VERSION ""

NS_ :

BS_:

BU_: BMoS ECU_CAN4

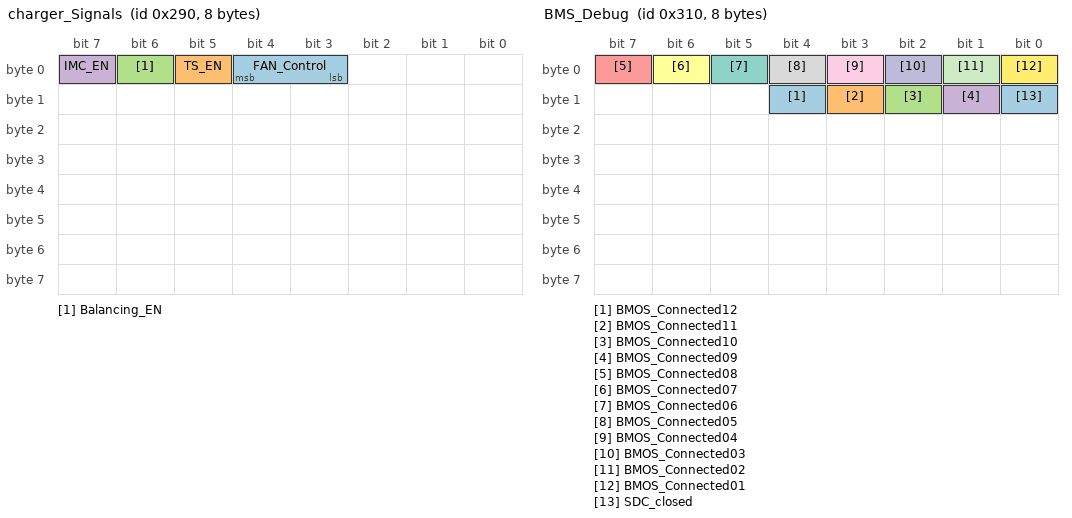
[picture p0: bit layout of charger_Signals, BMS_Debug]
BO_ 656 charger_Signals: 8 Vector__XXX
 SG_ FAN_Control : 3|2@1+ (1,0) [0|0] "" Vector__XXX
 SG_ TS_EN : 5|1@1+ (1,0) [0|1] "" Vector__XXX
 SG_ Balancing_EN : 6|1@1+ (1,0) [0|0] "" Vector__XXX
 SG_ IMC_EN : 7|1@1+ (1,0) [0|0] "" Vector__XXX

BO_ 1365 IMD: 8 Vector__XXX
 SG_ AMS_latched : 33|1@1+ (1,0) [0|1] "" Vector__XXX
 SG_ IMD_Latched : 32|1@1+ (1,0) [0|0] "" Vector__XXX

BO_ 624 charge_EN: 8 Vector__XXX
 SG_ Charge_EN : 0|1@1+ (1,0) [0|0] "" Vector__XXX
 SG_ Balance_FIN : 7|1@1+ (1,0) [0|0] "" Vector__XXX

BO_ 784 BMS_Debug: 8 Vector__XXX
 SG_ BMOS_Connected12 : 12|1@1+ (1,0) [0|0] "" Vector__XXX
 SG_ BMOS_Connected11 : 11|1@1+ (1,0) [0|0] "" Vector__XXX
 SG_ BMOS_Connected10 : 10|1@1+ (1,0) [0|0] "" Vector__XXX
 SG_ BMOS_Connected09 : 9|1@1+ (1,0) [0|0] "" Vector__XXX
 SG_ BMOS_Connected08 : 7|1@1+ (1,0) [0|0] "" Vector__XXX
 SG_ BMOS_Connected07 : 6|1@1+ (1,0) [0|0] "" Vector__XXX
 SG_ BMOS_Connected06 : 5|1@1+ (1,0) [0|0] "" Vector__XXX
 SG_ BMOS_Connected05 : 4|1@1+ (1,0) [0|0] "" Vector__XXX
 SG_ BMOS_Connected04 : 3|1@1+ (1,0) [0|0] "" Vector__XXX
 SG_ BMOS_Connected03 : 2|1@1+ (1,0) [0|0] "" Vector__XXX
 SG_ BMOS_Connected02 : 1|1@1+ (1,0) [0|0] "" Vector__XXX
 SG_ BMOS_Connected01 : 0|1@1+ (1,0) [0|0] "" Vector__XXX
 SG_ SDC_closed : 8|1@1+ (1,0) [0|0] "" Vector__XXX

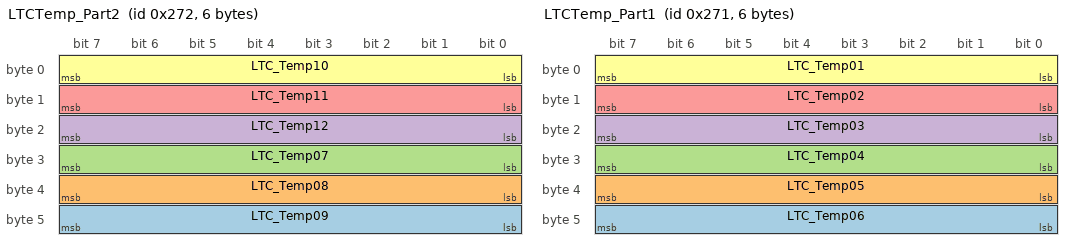
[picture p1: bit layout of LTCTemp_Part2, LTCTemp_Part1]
BO_ 626 LTCTemp_Part2: 6 BMoS
 SG_ LTC_Temp09 : 40|8@1- (1,0) [0|0] ""  ECU_CAN4
 SG_ LTC_Temp08 : 32|8@1- (1,0) [0|0] ""  ECU_CAN4
 SG_ LTC_Temp07 : 24|8@1- (1,0) [0|0] ""  ECU_CAN4
 SG_ LTC_Temp12 : 16|8@1- (1,0) [0|0] ""  ECU_CAN4
 SG_ LTC_Temp11 : 8|8@1- (1,0) [0|0] ""  ECU_CAN4
 SG_ LTC_Temp10 : 0|8@1- (1,0) [0|0] ""  ECU_CAN4

BO_ 625 LTCTemp_Part1: 6 BMoS
 SG_ LTC_Temp06 : 40|8@1- (1,0) [0|0] ""  ECU_CAN4
 SG_ LTC_Temp05 : 32|8@1- (1,0) [0|0] ""  ECU_CAN4
 SG_ LTC_Temp04 : 24|8@1- (1,0) [0|0] ""  ECU_CAN4
 SG_ LTC_Temp03 : 16|8@1- (1,0) [0|0] ""  ECU_CAN4
 SG_ LTC_Temp02 : 8|8@1- (1,0) [0|0] ""  ECU_CAN4
 SG_ LTC_Temp01 : 0|8@1- (1,0) [0|0] ""  ECU_CAN4

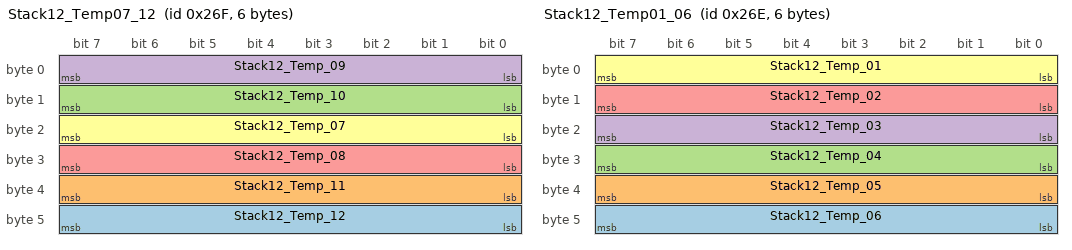
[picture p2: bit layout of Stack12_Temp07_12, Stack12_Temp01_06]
BO_ 623 Stack12_Temp07_12: 6 BMoS
 SG_ Stack12_Temp_12 : 40|8@1+ (1,0) [0|0] "°C" Vector__XXX
 SG_ Stack12_Temp_11 : 32|8@1+ (1,0) [0|0] "°C" Vector__XXX
 SG_ Stack12_Temp_10 : 8|8@1+ (1,0) [0|0] "°C" Vector__XXX
 SG_ Stack12_Temp_09 : 0|8@1+ (1,0) [0|0] "°C" Vector__XXX
 SG_ Stack12_Temp_08 : 24|8@1+ (1,0) [0|0] "°C"  ECU_CAN4
 SG_ Stack12_Temp_07 : 16|8@1+ (1,0) [0|0] "°C"  ECU_CAN4

BO_ 622 Stack12_Temp01_06: 6 BMoS
 SG_ Stack12_Temp_06 : 40|8@1+ (1,0) [0|0] "°C" Vector__XXX
 SG_ Stack12_Temp_05 : 32|8@1+ (1,0) [0|0] "°C" Vector__XXX
 SG_ Stack12_Temp_04 : 24|8@1+ (1,0) [0|0] "°C"  ECU_CAN4
 SG_ Stack12_Temp_03 : 16|8@1+ (1,0) [0|0] "°C"  ECU_CAN4
 SG_ Stack12_Temp_02 : 8|8@1+ (1,0) [0|0] "°C"  ECU_CAN4
 SG_ Stack12_Temp_01 : 0|8@1+ (1,0) [0|0] "°C"  ECU_CAN4

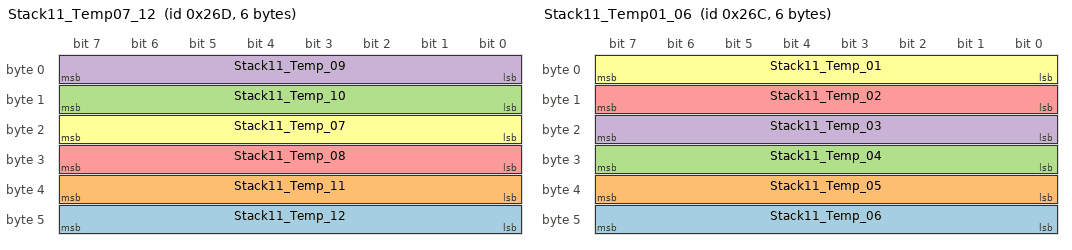
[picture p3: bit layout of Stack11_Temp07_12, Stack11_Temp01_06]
BO_ 621 Stack11_Temp07_12: 6 BMoS
 SG_ Stack11_Temp_12 : 40|8@1+ (1,0) [0|0] "°C" Vector__XXX
 SG_ Stack11_Temp_11 : 32|8@1+ (1,0) [0|0] "°C" Vector__XXX
 SG_ Stack11_Temp_10 : 8|8@1+ (1,0) [0|0] "°C" Vector__XXX
 SG_ Stack11_Temp_09 : 0|8@1+ (1,0) [0|0] "°C" Vector__XXX
 SG_ Stack11_Temp_08 : 24|8@1+ (1,0) [0|0] "°C"  ECU_CAN4
 SG_ Stack11_Temp_07 : 16|8@1+ (1,0) [0|0] "°C"  ECU_CAN4

BO_ 620 Stack11_Temp01_06: 6 BMoS
 SG_ Stack11_Temp_06 : 40|8@1+ (1,0) [0|0] "°C" Vector__XXX
 SG_ Stack11_Temp_05 : 32|8@1+ (1,0) [0|0] "°C" Vector__XXX
 SG_ Stack11_Temp_04 : 24|8@1+ (1,0) [0|0] "°C"  ECU_CAN4
 SG_ Stack11_Temp_03 : 16|8@1+ (1,0) [0|0] "°C"  ECU_CAN4
 SG_ Stack11_Temp_02 : 8|8@1+ (1,0) [0|0] "°C"  ECU_CAN4
 SG_ Stack11_Temp_01 : 0|8@1+ (1,0) [0|0] "°C"  ECU_CAN4

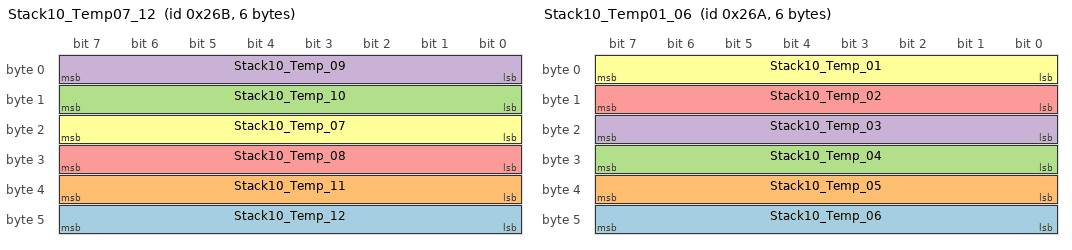
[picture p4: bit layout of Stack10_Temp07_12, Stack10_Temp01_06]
BO_ 619 Stack10_Temp07_12: 6 BMoS
 SG_ Stack10_Temp_12 : 40|8@1+ (1,0) [0|0] "°C" Vector__XXX
 SG_ Stack10_Temp_11 : 32|8@1+ (1,0) [0|0] "°C" Vector__XXX
 SG_ Stack10_Temp_10 : 8|8@1+ (1,0) [0|0] "°C" Vector__XXX
 SG_ Stack10_Temp_09 : 0|8@1+ (1,0) [0|0] "°C" Vector__XXX
 SG_ Stack10_Temp_08 : 24|8@1+ (1,0) [0|0] "°C"  ECU_CAN4
 SG_ Stack10_Temp_07 : 16|8@1+ (1,0) [0|0] "°C"  ECU_CAN4

BO_ 618 Stack10_Temp01_06: 6 BMoS
 SG_ Stack10_Temp_06 : 40|8@1+ (1,0) [0|0] "°C" Vector__XXX
 SG_ Stack10_Temp_05 : 32|8@1+ (1,0) [0|0] "°C" Vector__XXX
 SG_ Stack10_Temp_04 : 24|8@1+ (1,0) [0|0] "°C"  ECU_CAN4
 SG_ Stack10_Temp_03 : 16|8@1+ (1,0) [0|0] "°C"  ECU_CAN4
 SG_ Stack10_Temp_02 : 8|8@1+ (1,0) [0|0] "°C"  ECU_CAN4
 SG_ Stack10_Temp_01 : 0|8@1+ (1,0) [0|0] "°C"  ECU_CAN4

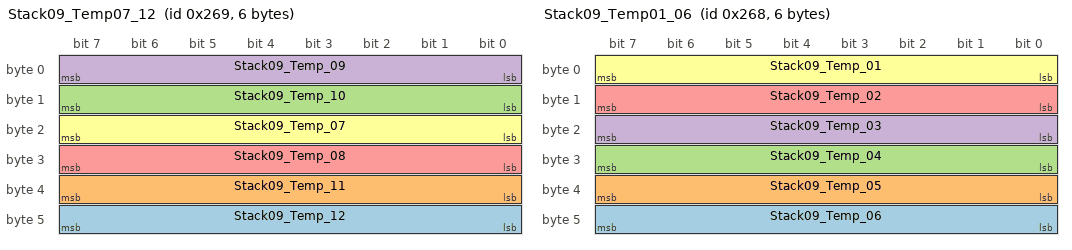
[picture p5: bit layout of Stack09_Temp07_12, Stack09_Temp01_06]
BO_ 617 Stack09_Temp07_12: 6 BMoS
 SG_ Stack09_Temp_12 : 40|8@1+ (1,0) [0|0] "°C" Vector__XXX
 SG_ Stack09_Temp_11 : 32|8@1+ (1,0) [0|0] "°C" Vector__XXX
 SG_ Stack09_Temp_10 : 8|8@1+ (1,0) [0|0] "°C" Vector__XXX
 SG_ Stack09_Temp_09 : 0|8@1+ (1,0) [0|0] "°C" Vector__XXX
 SG_ Stack09_Temp_08 : 24|8@1+ (1,0) [0|0] "°C"  ECU_CAN4
 SG_ Stack09_Temp_07 : 16|8@1+ (1,0) [0|0] "°C"  ECU_CAN4

BO_ 616 Stack09_Temp01_06: 6 BMoS
 SG_ Stack09_Temp_06 : 40|8@1+ (1,0) [0|0] "°C" Vector__XXX
 SG_ Stack09_Temp_05 : 32|8@1+ (1,0) [0|0] "°C" Vector__XXX
 SG_ Stack09_Temp_04 : 24|8@1+ (1,0) [0|0] "°C"  ECU_CAN4
 SG_ Stack09_Temp_03 : 16|8@1+ (1,0) [0|0] "°C"  ECU_CAN4
 SG_ Stack09_Temp_02 : 8|8@1+ (1,0) [0|0] "°C"  ECU_CAN4
 SG_ Stack09_Temp_01 : 0|8@1+ (1,0) [0|0] "°C"  ECU_CAN4

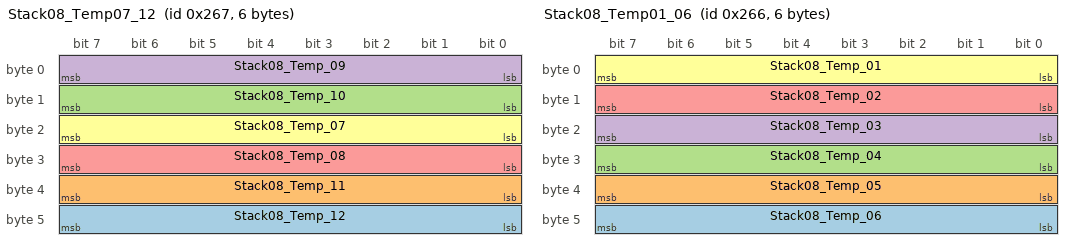
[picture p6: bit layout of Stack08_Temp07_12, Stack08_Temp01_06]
BO_ 615 Stack08_Temp07_12: 6 BMoS
 SG_ Stack08_Temp_12 : 40|8@1+ (1,0) [0|0] "°C" Vector__XXX
 SG_ Stack08_Temp_11 : 32|8@1+ (1,0) [0|0] "°C" Vector__XXX
 SG_ Stack08_Temp_10 : 8|8@1+ (1,0) [0|0] "°C" Vector__XXX
 SG_ Stack08_Temp_09 : 0|8@1+ (1,0) [0|0] "°C" Vector__XXX
 SG_ Stack08_Temp_08 : 24|8@1+ (1,0) [0|0] "°C"  ECU_CAN4
 SG_ Stack08_Temp_07 : 16|8@1+ (1,0) [0|0] "°C"  ECU_CAN4

BO_ 614 Stack08_Temp01_06: 6 BMoS
 SG_ Stack08_Temp_06 : 40|8@1+ (1,0) [0|0] "°C" Vector__XXX
 SG_ Stack08_Temp_05 : 32|8@1+ (1,0) [0|0] "°C" Vector__XXX
 SG_ Stack08_Temp_04 : 24|8@1+ (1,0) [0|0] "°C"  ECU_CAN4
 SG_ Stack08_Temp_03 : 16|8@1+ (1,0) [0|0] "°C"  ECU_CAN4
 SG_ Stack08_Temp_02 : 8|8@1+ (1,0) [0|0] "°C"  ECU_CAN4
 SG_ Stack08_Temp_01 : 0|8@1+ (1,0) [0|0] "°C"  ECU_CAN4

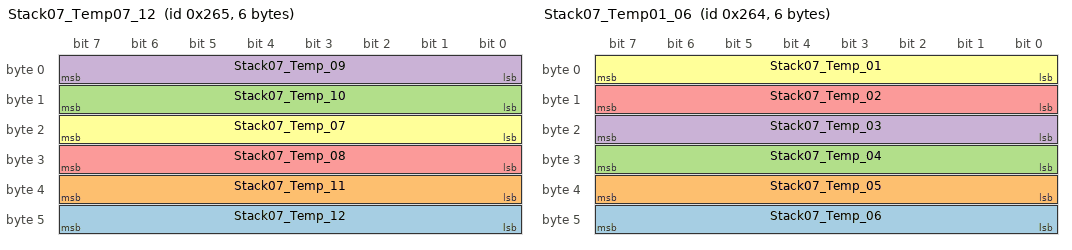
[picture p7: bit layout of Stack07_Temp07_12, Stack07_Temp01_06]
BO_ 613 Stack07_Temp07_12: 6 BMoS
 SG_ Stack07_Temp_12 : 40|8@1+ (1,0) [0|0] "°C" Vector__XXX
 SG_ Stack07_Temp_11 : 32|8@1+ (1,0) [0|0] "°C" Vector__XXX
 SG_ Stack07_Temp_10 : 8|8@1+ (1,0) [0|0] "°C" Vector__XXX
 SG_ Stack07_Temp_09 : 0|8@1+ (1,0) [0|0] "°C" Vector__XXX
 SG_ Stack07_Temp_08 : 24|8@1+ (1,0) [0|0] "°C"  ECU_CAN4
 SG_ Stack07_Temp_07 : 16|8@1+ (1,0) [0|0] "°C"  ECU_CAN4

BO_ 612 Stack07_Temp01_06: 6 BMoS
 SG_ Stack07_Temp_06 : 40|8@1+ (1,0) [0|0] "°C" Vector__XXX
 SG_ Stack07_Temp_05 : 32|8@1+ (1,0) [0|0] "°C" Vector__XXX
 SG_ Stack07_Temp_04 : 24|8@1+ (1,0) [0|0] "°C"  ECU_CAN4
 SG_ Stack07_Temp_03 : 16|8@1+ (1,0) [0|0] "°C"  ECU_CAN4
 SG_ Stack07_Temp_02 : 8|8@1+ (1,0) [0|0] "°C"  ECU_CAN4
 SG_ Stack07_Temp_01 : 0|8@1+ (1,0) [0|0] "°C"  ECU_CAN4

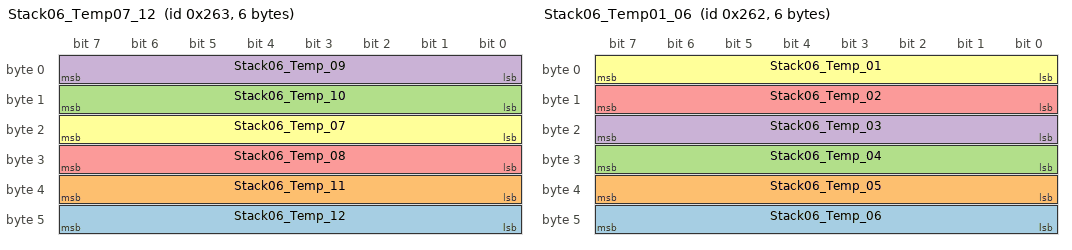
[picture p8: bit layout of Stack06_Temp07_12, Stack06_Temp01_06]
BO_ 611 Stack06_Temp07_12: 6 BMoS
 SG_ Stack06_Temp_12 : 40|8@1+ (1,0) [0|0] "°C" Vector__XXX
 SG_ Stack06_Temp_11 : 32|8@1+ (1,0) [0|0] "°C" Vector__XXX
 SG_ Stack06_Temp_10 : 8|8@1+ (1,0) [0|0] "°C" Vector__XXX
 SG_ Stack06_Temp_09 : 0|8@1+ (1,0) [0|0] "°C" Vector__XXX
 SG_ Stack06_Temp_08 : 24|8@1+ (1,0) [0|0] "°C"  ECU_CAN4
 SG_ Stack06_Temp_07 : 16|8@1+ (1,0) [0|0] "°C"  ECU_CAN4

BO_ 610 Stack06_Temp01_06: 6 BMoS
 SG_ Stack06_Temp_06 : 40|8@1+ (1,0) [0|0] "°C" Vector__XXX
 SG_ Stack06_Temp_05 : 32|8@1+ (1,0) [0|0] "°C" Vector__XXX
 SG_ Stack06_Temp_04 : 24|8@1+ (1,0) [0|0] "°C"  ECU_CAN4
 SG_ Stack06_Temp_03 : 16|8@1+ (1,0) [0|0] "°C"  ECU_CAN4
 SG_ Stack06_Temp_02 : 8|8@1+ (1,0) [0|0] "°C"  ECU_CAN4
 SG_ Stack06_Temp_01 : 0|8@1+ (1,0) [0|0] "°C"  ECU_CAN4

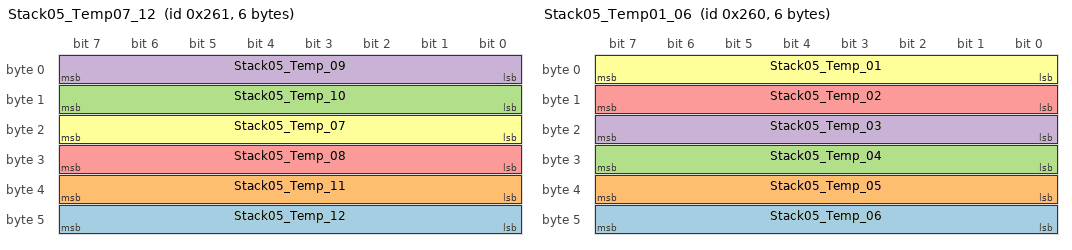
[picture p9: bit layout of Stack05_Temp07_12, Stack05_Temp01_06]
BO_ 609 Stack05_Temp07_12: 6 BMoS
 SG_ Stack05_Temp_12 : 40|8@1+ (1,0) [0|0] "°C" Vector__XXX
 SG_ Stack05_Temp_11 : 32|8@1+ (1,0) [0|0] "°C" Vector__XXX
 SG_ Stack05_Temp_10 : 8|8@1+ (1,0) [0|0] "°C" Vector__XXX
 SG_ Stack05_Temp_09 : 0|8@1+ (1,0) [0|0] "°C" Vector__XXX
 SG_ Stack05_Temp_08 : 24|8@1+ (1,0) [0|0] "°C"  ECU_CAN4
 SG_ Stack05_Temp_07 : 16|8@1+ (1,0) [0|0] "°C"  ECU_CAN4

BO_ 608 Stack05_Temp01_06: 6 BMoS
 SG_ Stack05_Temp_06 : 40|8@1+ (1,0) [0|0] "°C" Vector__XXX
 SG_ Stack05_Temp_05 : 32|8@1+ (1,0) [0|0] "°C" Vector__XXX
 SG_ Stack05_Temp_04 : 24|8@1+ (1,0) [0|0] "°C"  ECU_CAN4
 SG_ Stack05_Temp_03 : 16|8@1+ (1,0) [0|0] "°C"  ECU_CAN4
 SG_ Stack05_Temp_02 : 8|8@1+ (1,0) [0|0] "°C"  ECU_CAN4
 SG_ Stack05_Temp_01 : 0|8@1+ (1,0) [0|0] "°C"  ECU_CAN4

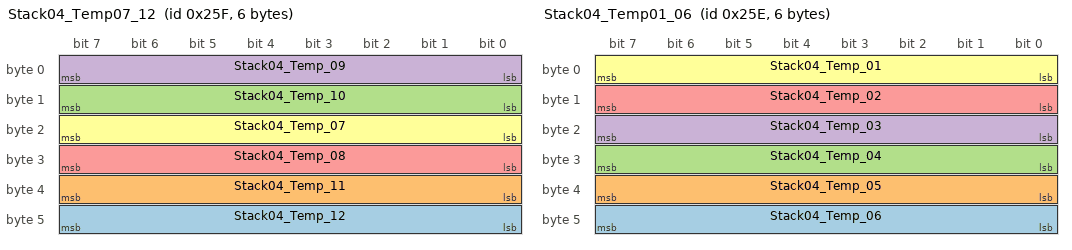
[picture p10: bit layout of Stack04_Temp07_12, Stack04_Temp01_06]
BO_ 607 Stack04_Temp07_12: 6 BMoS
 SG_ Stack04_Temp_12 : 40|8@1+ (1,0) [0|0] "°C" Vector__XXX
 SG_ Stack04_Temp_11 : 32|8@1+ (1,0) [0|0] "°C" Vector__XXX
 SG_ Stack04_Temp_10 : 8|8@1+ (1,0) [0|0] "°C" Vector__XXX
 SG_ Stack04_Temp_09 : 0|8@1+ (1,0) [0|0] "°C" Vector__XXX
 SG_ Stack04_Temp_08 : 24|8@1+ (1,0) [0|0] "°C"  ECU_CAN4
 SG_ Stack04_Temp_07 : 16|8@1+ (1,0) [0|0] "°C"  ECU_CAN4

BO_ 606 Stack04_Temp01_06: 6 BMoS
 SG_ Stack04_Temp_06 : 40|8@1+ (1,0) [0|0] "°C" Vector__XXX
 SG_ Stack04_Temp_05 : 32|8@1+ (1,0) [0|0] "°C" Vector__XXX
 SG_ Stack04_Temp_04 : 24|8@1+ (1,0) [0|0] "°C"  ECU_CAN4
 SG_ Stack04_Temp_03 : 16|8@1+ (1,0) [0|0] "°C"  ECU_CAN4
 SG_ Stack04_Temp_02 : 8|8@1+ (1,0) [0|0] "°C"  ECU_CAN4
 SG_ Stack04_Temp_01 : 0|8@1+ (1,0) [0|0] "°C"  ECU_CAN4

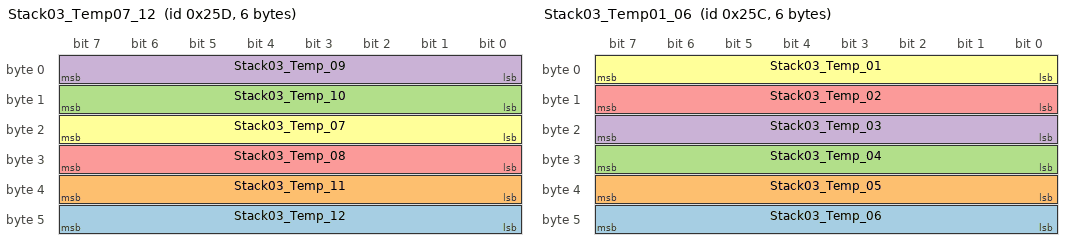
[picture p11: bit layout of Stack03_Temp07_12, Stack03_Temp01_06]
BO_ 605 Stack03_Temp07_12: 6 BMoS
 SG_ Stack03_Temp_12 : 40|8@1+ (1,0) [0|0] "°C" Vector__XXX
 SG_ Stack03_Temp_11 : 32|8@1+ (1,0) [0|0] "°C" Vector__XXX
 SG_ Stack03_Temp_10 : 8|8@1+ (1,0) [0|0] "°C" Vector__XXX
 SG_ Stack03_Temp_09 : 0|8@1+ (1,0) [0|0] "°C" Vector__XXX
 SG_ Stack03_Temp_08 : 24|8@1+ (1,0) [0|0] "°C"  ECU_CAN4
 SG_ Stack03_Temp_07 : 16|8@1+ (1,0) [0|0] "°C"  ECU_CAN4

BO_ 604 Stack03_Temp01_06: 6 BMoS
 SG_ Stack03_Temp_06 : 40|8@1+ (1,0) [0|0] "°C" Vector__XXX
 SG_ Stack03_Temp_05 : 32|8@1+ (1,0) [0|0] "°C" Vector__XXX
 SG_ Stack03_Temp_04 : 24|8@1+ (1,0) [0|0] "°C"  ECU_CAN4
 SG_ Stack03_Temp_03 : 16|8@1+ (1,0) [0|0] "°C"  ECU_CAN4
 SG_ Stack03_Temp_02 : 8|8@1+ (1,0) [0|0] "°C"  ECU_CAN4
 SG_ Stack03_Temp_01 : 0|8@1+ (1,0) [0|0] "°C"  ECU_CAN4

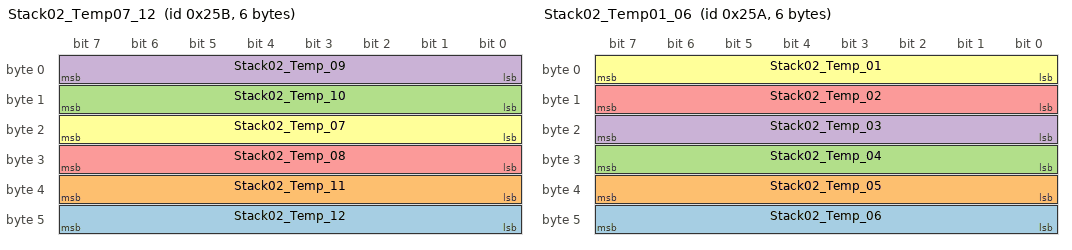
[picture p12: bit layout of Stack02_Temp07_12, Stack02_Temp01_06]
BO_ 603 Stack02_Temp07_12: 6 BMoS
 SG_ Stack02_Temp_12 : 40|8@1+ (1,0) [0|0] "°C" Vector__XXX
 SG_ Stack02_Temp_11 : 32|8@1+ (1,0) [0|0] "°C" Vector__XXX
 SG_ Stack02_Temp_10 : 8|8@1+ (1,0) [0|0] "°C" Vector__XXX
 SG_ Stack02_Temp_09 : 0|8@1+ (1,0) [0|0] "°C" Vector__XXX
 SG_ Stack02_Temp_08 : 24|8@1+ (1,0) [0|0] "°C"  ECU_CAN4
 SG_ Stack02_Temp_07 : 16|8@1+ (1,0) [0|0] "°C"  ECU_CAN4

BO_ 602 Stack02_Temp01_06: 6 BMoS
 SG_ Stack02_Temp_06 : 40|8@1+ (1,0) [0|0] "°C" Vector__XXX
 SG_ Stack02_Temp_05 : 32|8@1+ (1,0) [0|0] "°C" Vector__XXX
 SG_ Stack02_Temp_04 : 24|8@1+ (1,0) [0|0] "°C"  ECU_CAN4
 SG_ Stack02_Temp_03 : 16|8@1+ (1,0) [0|0] "°C"  ECU_CAN4
 SG_ Stack02_Temp_02 : 8|8@1+ (1,0) [0|0] "°C"  ECU_CAN4
 SG_ Stack02_Temp_01 : 0|8@1+ (1,0) [0|0] "°C"  ECU_CAN4

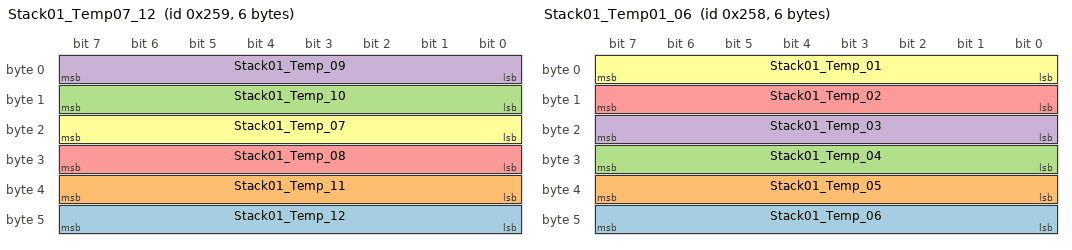
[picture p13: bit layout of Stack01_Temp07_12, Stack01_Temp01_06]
BO_ 601 Stack01_Temp07_12: 6 BMoS
 SG_ Stack01_Temp_12 : 40|8@1+ (1,0) [0|0] "°C" Vector__XXX
 SG_ Stack01_Temp_11 : 32|8@1+ (1,0) [0|0] "°C" Vector__XXX
 SG_ Stack01_Temp_10 : 8|8@1+ (1,0) [0|0] "°C" Vector__XXX
 SG_ Stack01_Temp_09 : 0|8@1+ (1,0) [0|0] "°C" Vector__XXX
 SG_ Stack01_Temp_08 : 24|8@1+ (1,0) [0|0] "°C"  ECU_CAN4
 SG_ Stack01_Temp_07 : 16|8@1+ (1,0) [0|0] "°C"  ECU_CAN4

BO_ 600 Stack01_Temp01_06: 6 BMoS
 SG_ Stack01_Temp_06 : 40|8@1+ (1,0) [0|0] "°C" Vector__XXX
 SG_ Stack01_Temp_05 : 32|8@1+ (1,0) [0|0] "°C" Vector__XXX
 SG_ Stack01_Temp_04 : 24|8@1+ (1,0) [0|0] "°C"  ECU_CAN4
 SG_ Stack01_Temp_03 : 16|8@1+ (1,0) [0|0] "°C"  ECU_CAN4
 SG_ Stack01_Temp_02 : 8|8@1+ (1,0) [0|0] "°C"  ECU_CAN4
 SG_ Stack01_Temp_01 : 0|8@1+ (1,0) [0|0] "°C"  ECU_CAN4

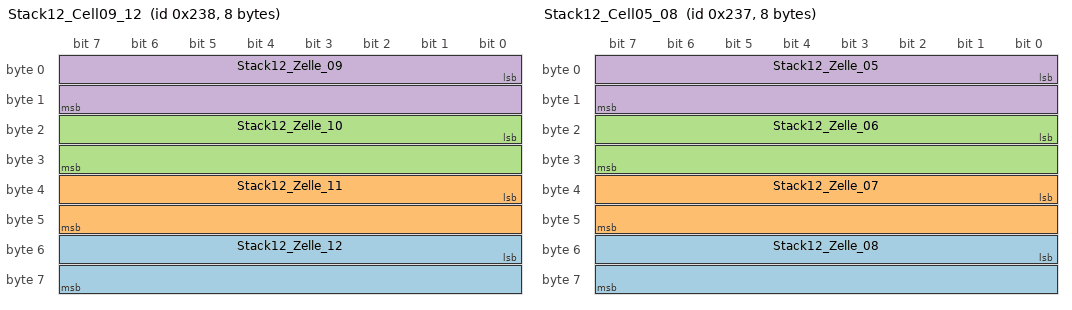
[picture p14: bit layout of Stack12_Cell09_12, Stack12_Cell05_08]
BO_ 568 Stack12_Cell09_12: 8 BMoS
 SG_ Stack12_Zelle_12 : 48|16@1+ (1,0) [0|0] "100 uV"  ECU_CAN4
 SG_ Stack12_Zelle_11 : 32|16@1+ (1,0) [0|0] "100 uV"  ECU_CAN4
 SG_ Stack12_Zelle_10 : 16|16@1+ (1,0) [0|0] "100 uV"  ECU_CAN4
 SG_ Stack12_Zelle_09 : 0|16@1+ (1,0) [0|0] "100 uV"  ECU_CAN4

BO_ 567 Stack12_Cell05_08: 8 BMoS
 SG_ Stack12_Zelle_08 : 48|16@1+ (1,0) [0|0] "100 uV"  ECU_CAN4
 SG_ Stack12_Zelle_07 : 32|16@1+ (1,0) [0|0] "100 uV"  ECU_CAN4
 SG_ Stack12_Zelle_06 : 16|16@1+ (1,0) [0|0] "100 uV"  ECU_CAN4
 SG_ Stack12_Zelle_05 : 0|16@1+ (1,0) [0|0] "100 uV"  ECU_CAN4

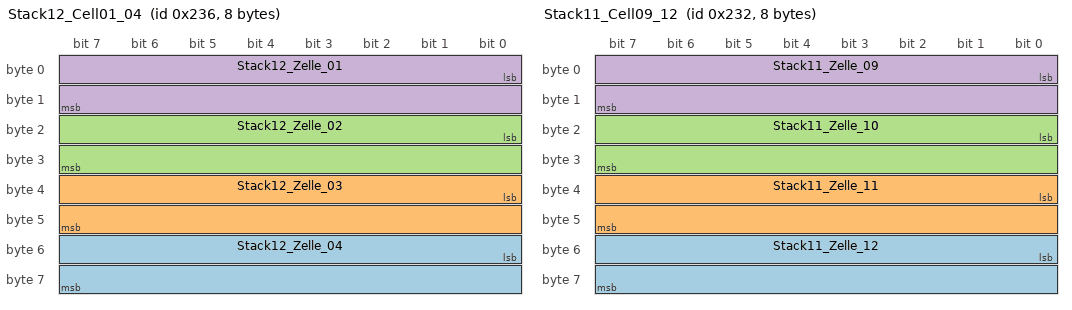
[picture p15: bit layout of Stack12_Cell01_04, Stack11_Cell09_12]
BO_ 566 Stack12_Cell01_04: 8 BMoS
 SG_ Stack12_Zelle_04 : 48|16@1+ (1,0) [0|0] "100 uV"  ECU_CAN4
 SG_ Stack12_Zelle_03 : 32|16@1+ (1,0) [0|0] "100 uV"  ECU_CAN4
 SG_ Stack12_Zelle_02 : 16|16@1+ (1,0) [0|0] "100 uV"  ECU_CAN4
 SG_ Stack12_Zelle_01 : 0|16@1+ (1,0) [0|0] "100 uV"  ECU_CAN4

BO_ 562 Stack11_Cell09_12: 8 BMoS
 SG_ Stack11_Zelle_12 : 48|16@1+ (1,0) [0|0] "100 uV"  ECU_CAN4
 SG_ Stack11_Zelle_11 : 32|16@1+ (1,0) [0|0] "100 uV"  ECU_CAN4
 SG_ Stack11_Zelle_10 : 16|16@1+ (1,0) [0|0] "100 uV"  ECU_CAN4
 SG_ Stack11_Zelle_09 : 0|16@1+ (1,0) [0|0] "100 uV"  ECU_CAN4

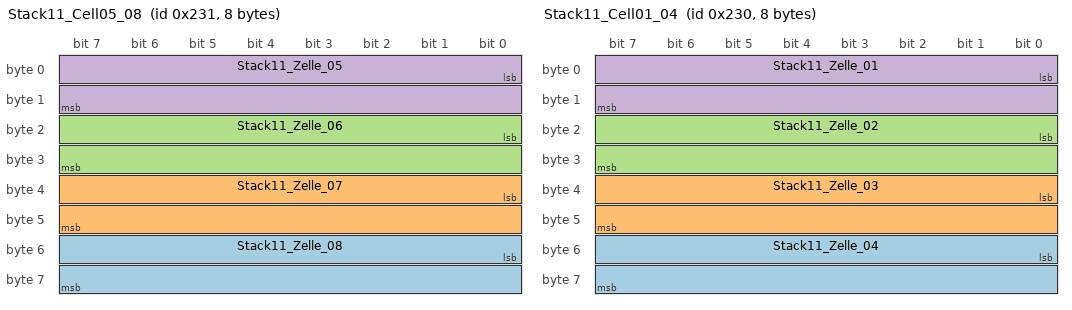
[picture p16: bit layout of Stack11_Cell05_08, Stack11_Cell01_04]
BO_ 561 Stack11_Cell05_08: 8 BMoS
 SG_ Stack11_Zelle_08 : 48|16@1+ (1,0) [0|0] "100 uV"  ECU_CAN4
 SG_ Stack11_Zelle_07 : 32|16@1+ (1,0) [0|0] "100 uV"  ECU_CAN4
 SG_ Stack11_Zelle_06 : 16|16@1+ (1,0) [0|0] "100 uV"  ECU_CAN4
 SG_ Stack11_Zelle_05 : 0|16@1+ (1,0) [0|0] "100 uV"  ECU_CAN4

BO_ 560 Stack11_Cell01_04: 8 BMoS
 SG_ Stack11_Zelle_04 : 48|16@1+ (1,0) [0|0] "100 uV"  ECU_CAN4
 SG_ Stack11_Zelle_03 : 32|16@1+ (1,0) [0|0] "100 uV"  ECU_CAN4
 SG_ Stack11_Zelle_02 : 16|16@1+ (1,0) [0|0] "100 uV"  ECU_CAN4
 SG_ Stack11_Zelle_01 : 0|16@1+ (1,0) [0|0] "100 uV"  ECU_CAN4

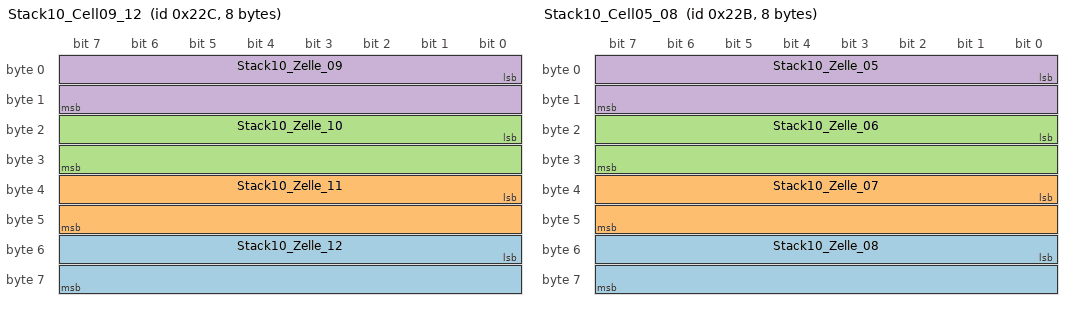
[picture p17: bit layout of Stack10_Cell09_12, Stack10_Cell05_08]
BO_ 556 Stack10_Cell09_12: 8 BMoS
 SG_ Stack10_Zelle_12 : 48|16@1+ (1,0) [0|0] "100 uV"  ECU_CAN4
 SG_ Stack10_Zelle_11 : 32|16@1+ (1,0) [0|0] "100 uV"  ECU_CAN4
 SG_ Stack10_Zelle_10 : 16|16@1+ (1,0) [0|0] "100 uV"  ECU_CAN4
 SG_ Stack10_Zelle_09 : 0|16@1+ (1,0) [0|0] "100 uV"  ECU_CAN4

BO_ 555 Stack10_Cell05_08: 8 BMoS
 SG_ Stack10_Zelle_08 : 48|16@1+ (1,0) [0|0] "100 uV"  ECU_CAN4
 SG_ Stack10_Zelle_07 : 32|16@1+ (1,0) [0|0] "100 uV"  ECU_CAN4
 SG_ Stack10_Zelle_06 : 16|16@1+ (1,0) [0|0] "100 uV"  ECU_CAN4
 SG_ Stack10_Zelle_05 : 0|16@1+ (1,0) [0|0] "100 uV"  ECU_CAN4

BO_ 554 Stack10_Cell01_04: 8 BMoS
 SG_ Stack10_Zelle_04 : 48|16@1+ (1,0) [0|0] "100 uV"  ECU_CAN4
 SG_ Stack10_Zelle_03 : 32|16@1+ (1,0) [0|0] "100 uV"  ECU_CAN4
 SG_ Stack10_Zelle_02 : 16|16@1+ (1,0) [0|0] "100 uV"  ECU_CAN4
 SG_ Stack10_Zelle_01 : 0|16@1+ (1,0) [0|0] "100 uV"  ECU_CAN4

BO_ 550 Stack09_Cell09_12: 8 BMoS
 SG_ Stack09_Zelle_12 : 48|16@1+ (1,0) [0|0] "100 uV"  ECU_CAN4
 SG_ Stack09_Zelle_11 : 32|16@1+ (1,0) [0|0] "100 uV"  ECU_CAN4
 SG_ Stack09_Zelle_10 : 16|16@1+ (1,0) [0|0] "100 uV"  ECU_CAN4
 SG_ Stack09_Zelle_09 : 0|16@1+ (1,0) [0|0] "100 uV"  ECU_CAN4

BO_ 549 Stack09_Cell05_08: 8 BMoS
 SG_ Stack09_Zelle_08 : 48|16@1+ (1,0) [0|0] "100 uV"  ECU_CAN4
 SG_ Stack09_Zelle_07 : 32|16@1+ (1,0) [0|0] "100 uV"  ECU_CAN4
 SG_ Stack09_Zelle_06 : 16|16@1+ (1,0) [0|0] "100 uV"  ECU_CAN4
 SG_ Stack09_Zelle_05 : 0|16@1+ (1,0) [0|0] "100 uV"  ECU_CAN4

BO_ 548 Stack09_Cell01_04: 8 BMoS
 SG_ Stack09_Zelle_04 : 48|16@1+ (1,0) [0|0] "100 uV"  ECU_CAN4
 SG_ Stack09_Zelle_03 : 32|16@1+ (1,0) [0|0] "100 uV"  ECU_CAN4
 SG_ Stack09_Zelle_02 : 16|16@1+ (1,0) [0|0] "100 uV"  ECU_CAN4
 SG_ Stack09_Zelle_01 : 0|16@1+ (1,0) [0|0] "100 uV"  ECU_CAN4

BO_ 544 Stack08_Cell09_12: 8 BMoS
 SG_ Stack08_Zelle_12 : 48|16@1+ (1,0) [0|0] "100 uV"  ECU_CAN4
 SG_ Stack08_Zelle_11 : 32|16@1+ (1,0) [0|0] "100 uV"  ECU_CAN4
 SG_ Stack08_Zelle_10 : 16|16@1+ (1,0) [0|0] "100 uV"  ECU_CAN4
 SG_ Stack08_Zelle_09 : 0|16@1+ (1,0) [0|0] "100 uV"  ECU_CAN4

BO_ 543 Stack08_Cell05_08: 8 BMoS
 SG_ Stack08_Zelle_08 : 48|16@1+ (1,0) [0|0] "100 uV"  ECU_CAN4
 SG_ Stack08_Zelle_07 : 32|16@1+ (1,0) [0|0] "100 uV"  ECU_CAN4
 SG_ Stack08_Zelle_06 : 16|16@1+ (1,0) [0|0] "100 uV"  ECU_CAN4
 SG_ Stack08_Zelle_05 : 0|16@1+ (1,0) [0|0] "100 uV"  ECU_CAN4

BO_ 542 Stack08_Cell01_04: 8 BMoS
 SG_ Stack08_Zelle_04 : 48|16@1+ (1,0) [0|0] "100 uV"  ECU_CAN4
 SG_ Stack08_Zelle_03 : 32|16@1+ (1,0) [0|0] "100 uV"  ECU_CAN4
 SG_ Stack08_Zelle_02 : 16|16@1+ (1,0) [0|0] "100 uV"  ECU_CAN4
 SG_ Stack08_Zelle_01 : 0|16@1+ (1,0) [0|0] "100 uV"  ECU_CAN4

BO_ 538 Stack07_Cell09_12: 8 BMoS
 SG_ Stack07_Zelle_12 : 48|16@1+ (1,0) [0|0] "100 uV"  ECU_CAN4
 SG_ Stack07_Zelle_11 : 32|16@1+ (1,0) [0|0] "100 uV"  ECU_CAN4
 SG_ Stack07_Zelle_10 : 16|16@1+ (1,0) [0|0] "100 uV"  ECU_CAN4
 SG_ Stack07_Zelle_09 : 0|16@1+ (1,0) [0|0] "100 uV"  ECU_CAN4

BO_ 537 Stack07_Cell05_08: 8 BMoS
 SG_ Stack07_Zelle_08 : 48|16@1+ (1,0) [0|0] "100 uV"  ECU_CAN4
 SG_ Stack07_Zelle_07 : 32|16@1+ (1,0) [0|0] "100 uV"  ECU_CAN4
 SG_ Stack07_Zelle_06 : 16|16@1+ (1,0) [0|0] "100 uV"  ECU_CAN4
 SG_ Stack07_Zelle_05 : 0|16@1+ (1,0) [0|0] "100 uV"  ECU_CAN4

BO_ 536 Stack07_Cell01_04: 8 BMoS
 SG_ Stack07_Zelle_04 : 48|16@1+ (1,0) [0|0] "100 uV"  ECU_CAN4
 SG_ Stack07_Zelle_03 : 32|16@1+ (1,0) [0|0] "100 uV"  ECU_CAN4
 SG_ Stack07_Zelle_02 : 16|16@1+ (1,0) [0|0] "100 uV"  ECU_CAN4
 SG_ Stack07_Zelle_01 : 0|16@1+ (1,0) [0|0] "100 uV"  ECU_CAN4

BO_ 532 Stack06_Cell09_12: 8 BMoS
 SG_ Stack06_Zelle_12 : 48|16@1+ (1,0) [0|0] "100 uV"  ECU_CAN4
 SG_ Stack06_Zelle_11 : 32|16@1+ (1,0) [0|0] "100 uV"  ECU_CAN4
 SG_ Stack06_Zelle_10 : 16|16@1+ (1,0) [0|0] "100 uV"  ECU_CAN4
 SG_ Stack06_Zelle_09 : 0|16@1+ (1,0) [0|0] "100 uV"  ECU_CAN4

BO_ 531 Stack06_Cell05_08: 8 BMoS
 SG_ Stack06_Zelle_08 : 48|16@1+ (1,0) [0|0] "100 uV"  ECU_CAN4
 SG_ Stack06_Zelle_07 : 32|16@1+ (1,0) [0|0] "100 uV"  ECU_CAN4
 SG_ Stack06_Zelle_06 : 16|16@1+ (1,0) [0|0] "100 uV"  ECU_CAN4
 SG_ Stack06_Zelle_05 : 0|16@1+ (1,0) [0|0] "100 uV"  ECU_CAN4

BO_ 530 Stack06_Cell01_04: 8 BMoS
 SG_ Stack06_Zelle_04 : 48|16@1+ (1,0) [0|0] "100 uV"  ECU_CAN4
 SG_ Stack06_Zelle_03 : 32|16@1+ (1,0) [0|0] "100 uV"  ECU_CAN4
 SG_ Stack06_Zelle_02 : 16|16@1+ (1,0) [0|0] "100 uV"  ECU_CAN4
 SG_ Stack06_Zelle_01 : 0|16@1+ (1,0) [0|0] "100 uV"  ECU_CAN4

BO_ 526 Stack05_Cell09_12: 8 BMoS
 SG_ Stack05_Zelle_12 : 48|16@1+ (1,0) [0|0] "100 uV"  ECU_CAN4
 SG_ Stack05_Zelle_11 : 32|16@1+ (1,0) [0|0] "100 uV"  ECU_CAN4
 SG_ Stack05_Zelle_10 : 16|16@1+ (1,0) [0|0] "100 uV"  ECU_CAN4
 SG_ Stack05_Zelle_09 : 0|16@1+ (1,0) [0|0] "100 uV"  ECU_CAN4

BO_ 525 Stack05_Cell05_08: 8 BMoS
 SG_ Stack05_Zelle_08 : 48|16@1+ (1,0) [0|0] "100 uV"  ECU_CAN4
 SG_ Stack05_Zelle_07 : 32|16@1+ (1,0) [0|0] "100 uV"  ECU_CAN4
 SG_ Stack05_Zelle_06 : 16|16@1+ (1,0) [0|0] "100 uV"  ECU_CAN4
 SG_ Stack05_Zelle_05 : 0|16@1+ (1,0) [0|0] "100 uV"  ECU_CAN4

BO_ 524 Stack05_Cell01_04: 8 BMoS
 SG_ Stack05_Zelle_04 : 48|16@1+ (1,0) [0|0] "100 uV"  ECU_CAN4
 SG_ Stack05_Zelle_03 : 32|16@1+ (1,0) [0|0] "100 uV"  ECU_CAN4
 SG_ Stack05_Zelle_02 : 16|16@1+ (1,0) [0|0] "100 uV"  ECU_CAN4
 SG_ Stack05_Zelle_01 : 0|16@1+ (1,0) [0|0] "100 uV"  ECU_CAN4

BO_ 520 Stack04_Cell09_12: 8 BMoS
 SG_ Stack04_Zelle_12 : 48|16@1+ (1,0) [0|0] "100 uV"  ECU_CAN4
 SG_ Stack04_Zelle_11 : 32|16@1+ (1,0) [0|0] "100 uV"  ECU_CAN4
 SG_ Stack04_Zelle_10 : 16|16@1+ (1,0) [0|0] "100 uV"  ECU_CAN4
 SG_ Stack04_Zelle_09 : 0|16@1+ (1,0) [0|0] "100 uV"  ECU_CAN4

BO_ 519 Stack04_Cell05_08: 8 BMoS
 SG_ Stack04_Zelle_08 : 48|16@1+ (1,0) [0|0] "100 uV"  ECU_CAN4
 SG_ Stack04_Zelle_07 : 32|16@1+ (1,0) [0|0] "100 uV"  ECU_CAN4
 SG_ Stack04_Zelle_06 : 16|16@1+ (1,0) [0|0] "100 uV"  ECU_CAN4
 SG_ Stack04_Zelle_05 : 0|16@1+ (1,0) [0|0] "100 uV"  ECU_CAN4

BO_ 518 Stack04_Cell01_04: 8 BMoS
 SG_ Stack04_Zelle_04 : 48|16@1+ (1,0) [0|0] "100 uV"  ECU_CAN4
 SG_ Stack04_Zelle_03 : 32|16@1+ (1,0) [0|0] "100 uV"  ECU_CAN4
 SG_ Stack04_Zelle_02 : 16|16@1+ (1,0) [0|0] "100 uV"  ECU_CAN4
 SG_ Stack04_Zelle_01 : 0|16@1+ (1,0) [0|0] "100 uV"  ECU_CAN4

BO_ 514 Stack03_Cell09_12: 8 BMoS
 SG_ Stack03_Zelle_12 : 48|16@1+ (1,0) [0|0] "100 uV"  ECU_CAN4
 SG_ Stack03_Zelle_11 : 32|16@1+ (1,0) [0|0] "100 uV"  ECU_CAN4
 SG_ Stack03_Zelle_10 : 16|16@1+ (1,0) [0|0] "100 uV"  ECU_CAN4
 SG_ Stack03_Zelle_09 : 0|16@1+ (1,0) [0|0] "100 uV"  ECU_CAN4

BO_ 513 Stack03_Cell05_08: 8 BMoS
 SG_ Stack03_Zelle_08 : 48|16@1+ (1,0) [0|0] "100 uV"  ECU_CAN4
 SG_ Stack03_Zelle_07 : 32|16@1+ (1,0) [0|0] "100 uV"  ECU_CAN4
 SG_ Stack03_Zelle_06 : 16|16@1+ (1,0) [0|0] "100 uV"  ECU_CAN4
 SG_ Stack03_Zelle_05 : 0|16@1+ (1,0) [0|0] "100 uV"  ECU_CAN4

BO_ 512 Stack03_Cell01_04: 8 BMoS
 SG_ Stack03_Zelle_04 : 48|16@1+ (1,0) [0|0] "100 uV"  ECU_CAN4
 SG_ Stack03_Zelle_03 : 32|16@1+ (1,0) [0|0] "100 uV"  ECU_CAN4
 SG_ Stack03_Zelle_02 : 16|16@1+ (1,0) [0|0] "100 uV"  ECU_CAN4
 SG_ Stack03_Zelle_01 : 0|16@1+ (1,0) [0|0] "100 uV"  ECU_CAN4

BO_ 508 Stack02_Cell09_12: 8 BMoS
 SG_ Stack02_Zelle_12 : 48|16@1+ (1,0) [0|0] "100 uV"  ECU_CAN4
 SG_ Stack02_Zelle_11 : 32|16@1+ (1,0) [0|0] "100 uV"  ECU_CAN4
 SG_ Stack02_Zelle_10 : 16|16@1+ (1,0) [0|0] "100 uV"  ECU_CAN4
 SG_ Stack02_Zelle_09 : 0|16@1+ (1,0) [0|0] "100 uV"  ECU_CAN4

BO_ 507 Stack02_Cell05_08: 8 BMoS
 SG_ Stack02_Zelle_08 : 48|16@1+ (1,0) [0|0] "100 uV"  ECU_CAN4
 SG_ Stack02_Zelle_07 : 32|16@1+ (1,0) [0|0] "100 uV"  ECU_CAN4
 SG_ Stack02_Zelle_06 : 16|16@1+ (1,0) [0|0] "100 uV"  ECU_CAN4
 SG_ Stack02_Zelle_05 : 0|16@1+ (1,0) [0|0] "100 uV"  ECU_CAN4

BO_ 506 Stack02_Cell01_04: 8 BMoS
 SG_ Stack02_Zelle_04 : 48|16@1+ (1,0) [0|0] "100 uV"  ECU_CAN4
 SG_ Stack02_Zelle_03 : 32|16@1+ (1,0) [0|0] "100 uV"  ECU_CAN4
 SG_ Stack02_Zelle_02 : 16|16@1+ (1,0) [0|0] "100 uV"  ECU_CAN4
 SG_ Stack02_Zelle_01 : 0|16@1+ (1,0) [0|0] "100 uV"  ECU_CAN4

BO_ 502 Stack01_Cell09_12: 8 BMoS
 SG_ Stack01_Zelle_12 : 48|16@1+ (1,0) [0|0] "100 uV"  ECU_CAN4
 SG_ Stack01_Zelle_11 : 32|16@1+ (1,0) [0|0] "100 uV"  ECU_CAN4
 SG_ Stack01_Zelle_10 : 16|16@1+ (1,0) [0|0] "100 uV"  ECU_CAN4
 SG_ Stack01_Zelle_09 : 0|16@1+ (1,0) [0|0] "100 uV"  ECU_CAN4

BO_ 501 Stack01_Cell05_08: 8 BMoS
 SG_ Stack01_Zelle_08 : 48|16@1+ (1,0) [0|0] "100 uV"  ECU_CAN4
 SG_ Stack01_Zelle_07 : 32|16@1+ (1,0) [0|0] "100 uV"  ECU_CAN4
 SG_ Stack01_Zelle_06 : 16|16@1+ (1,0) [0|0] "100 uV"  ECU_CAN4
 SG_ Stack01_Zelle_05 : 0|16@1+ (1,0) [0|0] "100 uV"  ECU_CAN4

BO_ 500 Stack01_Cell01_04: 8 BMoS
 SG_ Stack01_Zelle_04 : 48|16@1+ (1,0) [0|0] "100 uV"  ECU_CAN4
 SG_ Stack01_Zelle_03 : 32|16@1+ (1,0) [0|0] "100 uV"  ECU_CAN4
 SG_ Stack01_Zelle_02 : 16|16@1+ (1,0) [0|0] "100 uV"  ECU_CAN4
 SG_ Stack01_Zelle_01 : 0|16@1+ (1,0) [0|0] "100 uV"  ECU_CAN4

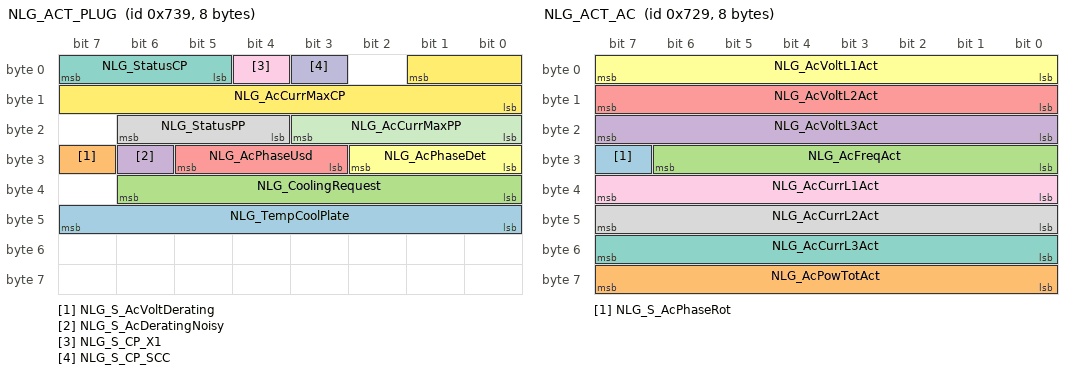
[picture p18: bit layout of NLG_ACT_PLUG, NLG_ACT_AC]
BO_ 1849 NLG_ACT_PLUG: 8 NLG6
 SG_ NLG_TempCoolPlate : 47|8@0+ (1,-50) [-50|204] "GradC"  Control
 SG_ NLG_S_AcVoltDerating : 31|1@0+ (1,0) [0|1] ""  Control
 SG_ NLG_CoolingRequest : 38|7@0+ (1,0) [0|100] "%"  Control
 SG_ NLG_S_AcDeratingNoisy : 30|1@0+ (1,0) [0|1] ""  Control
 SG_ NLG_AcPhaseUsd : 29|3@0+ (1,0) [0|7] ""  Control
 SG_ NLG_AcPhaseDet : 26|3@0+ (1,0) [0|7] ""  Control
 SG_ NLG_StatusCP : 7|3@0+ (1,0) [0|7] ""  Control
 SG_ NLG_StatusPP : 22|3@0+ (1,0) [0|7] ""  Control
 SG_ NLG_S_CP_X1 : 4|1@0+ (1,0) [0|1] ""  Control
 SG_ NLG_S_CP_SCC : 3|1@0+ (1,0) [0|1] ""  Control
 SG_ NLG_AcCurrMaxPP : 19|4@0+ (1,0) [0|15] ""  Control
 SG_ NLG_AcCurrMaxCP : 1|10@0+ (0.1,0) [0|80] "A"  Control

BO_ 1113 D_RS_NLG: 8 NLG6
 SG_ DiagDataResponse : 16|48@1+ (1,0) [0|0] ""  Control
 SG_ DiagTPCI : 8|8@1+ (1,0) [0|0] ""  Control
 SG_ DiagTA : 0|8@1+ (1,0) [0|0] ""  Control

BO_ 1105 D_RQ_NLG: 8 Control
 SG_ DiagDataRequest : 16|48@1+ (1,0) [0|0] ""  NLG6
 SG_ DiagTPCI : 8|8@1+ (1,0) [0|0] ""  NLG6
 SG_ DiagTA : 0|8@1+ (1,0) [0|0] ""  NLG6

BO_ 1089 D_RQ_UDS: 8 Control
 SG_ FunctionalData : 0|64@1- (1,0) [0|0] ""  NLG6

BO_ 2600147972 XCP_DTO_NLG: 8 NLG6
 SG_ XCP_DTO_NLG : 7|64@0+ (1,0) [0|0] ""  Control

BO_ 2600147968 XCP_CRO_NLG: 8 Control
 SG_ XCP_CRO_NLG : 7|64@0+ (1,0) [0|0] ""  NLG6

BO_ 1049 NLG_PARAM_TX: 8 NLG6
 SG_ NLG_PARAM_RP : 7|64@0+ (1,0) [0|1.844674407371E+019] ""  Control

BO_ 1041 NLG_PARAM_RX: 8 Control
 SG_ NLG_PARAM_RQ : 7|64@0+ (1,0) [0|1.844674407371E+019] ""  NLG6

BO_ 1833 NLG_ACT_AC: 8 NLG6
 SG_ NLG_S_AcPhaseRot : 31|1@0+ (1,0) [0|1] ""  Control
 SG_ NLG_AcPowTotAct : 63|8@0+ (100,0) [0|25000] "W"  Control
 SG_ NLG_AcFreqAct : 30|7@0+ (1,0) [0|127] "Hz"  Control
 SG_ NLG_AcVoltL3Act : 23|8@0+ (2,0) [0|510] "V"  Control
 SG_ NLG_AcVoltL2Act : 15|8@0+ (2,0) [0|510] "V"  Control
 SG_ NLG_AcVoltL1Act : 7|8@0+ (2,0) [0|510] "V"  Control
 SG_ NLG_AcCurrL3Act : 55|8@0+ (1,-127) [-127|127] "A"  Control
 SG_ NLG_AcCurrL2Act : 47|8@0+ (1,-127) [-127|127] "A"  Control
 SG_ NLG_AcCurrL1Act : 39|8@0+ (1,-127) [-127|127] "A"  Control

BO_ 1832 NLG_ACT_LIM: 8 NLG6
 SG_ NLG_AcCurrHwAvl : 55|8@0+ (0.5,0) [0|100] "A"  Control
 SG_ NLG_S_HwEnable : 58|1@0+ (1,0) [0|1] ""  Control
 SG_ NLG_S_AcDet : 60|1@0+ (1,0) [0|1] ""  Control
 SG_ NLG_S_ConLocked : 61|1@0+ (1,0) [0|1] ""  Control
 SG_ NLG_S_CtrlPilotDet : 62|1@0+ (1,0) [0|1] ""  Control
 SG_ NLG_S_ProximityDet : 63|1@0+ (1,0) [0|1] ""  Control
 SG_ NLG_S_HwWakeup : 59|1@0+ (1,0) [0|1] ""  Control
 SG_ NLG_StateAct : 23|3@0+ (1,0) [0|7] ""  Control
 SG_ NLG_StateCtrlPilot : 7|3@0+ (1,0) [0|7] ""  Control
 SG_ NLG_S_ProximityLim : 39|1@0+ (1,0) [0|1] ""  Control
 SG_ NLG_S_IntTempLim : 36|1@0+ (1,0) [0|1] ""  Control
 SG_ NLG_S_CtrlPilotLim : 38|1@0+ (1,0) [0|1] ""  Control
 SG_ NLG_S_ConTempLim : 37|1@0+ (1,0) [0|1] ""  Control
 SG_ NLG_S_AcCurrLim : 35|1@0+ (1,0) [0|1] ""  Control
 SG_ NLG_S_War : 56|1@0+ (1,0) [0|1] ""  Control
 SG_ NLG_S_Err : 57|1@0+ (1,0) [0|1] ""  Control
 SG_ NLG_S_DcHvVoltLim : 19|1@0+ (1,0) [0|1] ""  Control
 SG_ NLG_S_DcHvCurrLim : 20|1@0+ (1,0) [0|1] ""  Control
 SG_ NLG_AcCurrMaxAct : 34|11@0+ (0.1,-102.4) [-100|100] "A"  Control
 SG_ NLG_DcHvVoltAct : 4|13@0+ (0.1,0) [0|800] "V"  Control
 SG_ NLG_DcHvCurrAct : 18|11@0+ (0.1,-102.4) [-100|100] "A"  Control

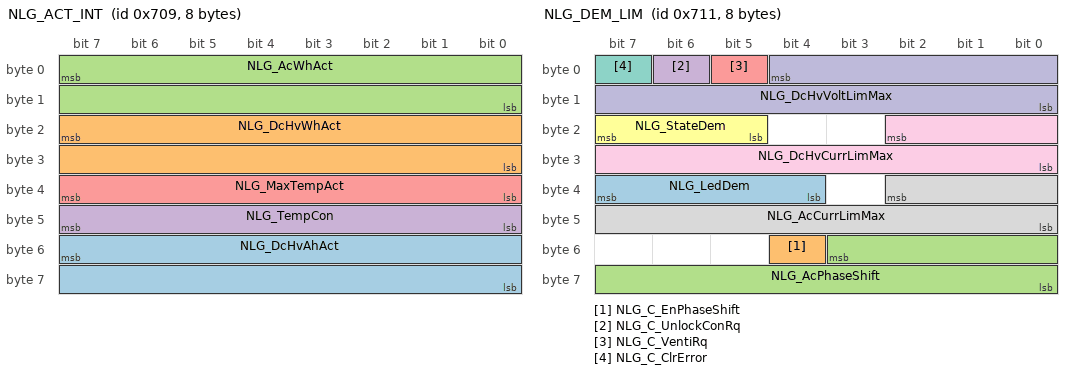
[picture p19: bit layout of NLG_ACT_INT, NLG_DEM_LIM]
BO_ 1801 NLG_ACT_INT: 8 NLG6
 SG_ NLG_DcHvAhAct : 55|16@0+ (0.01,0) [0|655.35] "Ah"  Control
 SG_ NLG_DcHvWhAct : 23|16@0+ (1,0) [0|65535] "Wh"  Control
 SG_ NLG_AcWhAct : 7|16@0+ (1,0) [0|65535] "Wh"  Control
 SG_ NLG_TempCon : 47|8@0+ (1,-50) [-50|204] "GradC"  Control
 SG_ NLG_MaxTempAct : 39|8@0+ (1,-50) [-50|204] "GradC"  Control

BO_ 1945 NLG_ACT_ERR: 8 NLG6
 SG_ NLG_E_LatchFPGA : 29|1@0+ (1,0) [0|1] ""  Control
 SG_ NLG_E_Inernal : 12|1@0+ (1,0) [0|1] ""  Control
 SG_ NLG_E_AcInterruption : 18|1@0+ (1,0) [0|1] ""  Control
 SG_ NLG_W_PRELOAD : 59|1@0+ (1,0) [0|1] ""  Control
 SG_ NLG_W_TempInt : 41|1@0+ (1,0) [0|1] ""  Control
 SG_ NLG_E_TempCon : 20|1@0+ (1,0) [0|1] ""  Control
 SG_ NLG_E_DcHvVoltRange : 19|1@0+ (1,0) [0|1] ""  Control
 SG_ NLG_E_UZK : 28|1@0+ (1,0) [0|1] ""  Control
 SG_ NLG_E_TPON : 27|1@0+ (1,0) [0|1] ""  Control
 SG_ NLG_E_BURST : 26|1@0+ (1,0) [0|1] ""  Control
 SG_ NLG_E_PRELOAD : 25|1@0+ (1,0) [0|1] ""  Control
 SG_ NLG_E_TempInt : 13|1@0+ (1,0) [0|1] ""  Control
 SG_ NLG_W_FPGA : 56|1@0+ (1,0) [0|1] ""  Control
 SG_ NLG_W_CanTimeout : 48|1@0+ (1,0) [0|1] ""  Control
 SG_ NLG_E_WrongFPGA : 1|1@0+ (1,0) [0|1] ""  Control
 SG_ NLG_W_AcVoltage : 57|1@0+ (1,0) [0|1] ""  Control
 SG_ NLG_W_AcFrequency : 58|1@0+ (1,0) [0|1] ""  Control
 SG_ NLG_W_ConLocked : 55|1@0+ (1,0) [0|1] ""  Control
 SG_ NLG_E_OverTemp : 31|1@0+ (1,0) [0|1] ""  Control
 SG_ NLG_W_PowRed : 40|1@0+ (1,0) [0|1] ""  Control
 SG_ NLG_E_WrongHW : 0|1@0+ (1,0) [0|1] ""  Control
 SG_ NLG_E_ConLocked : 21|1@0+ (1,0) [0|1] ""  Control
 SG_ NLG_E_IntSupply : 15|1@0+ (1,0) [0|1] ""  Control
 SG_ NLG_E_DcHvVoltRed : 14|1@0+ (1,0) [0|1] ""  Control
 SG_ NLG_E_HvIsoPos : 9|1@0+ (1,0) [0|1] ""  Control
 SG_ NLG_E_HvIsoNeg : 10|1@0+ (1,0) [0|1] ""  Control
 SG_ NLG_E_NVSRam : 5|1@0+ (1,0) [0|1] ""  Control
 SG_ NLG_E_FpgaInit : 2|1@0+ (1,0) [0|1] ""  Control
 SG_ NLG_E_Flash : 6|1@0+ (1,0) [0|1] ""  Control
 SG_ NLG_E_Interlock : 22|1@0+ (1,0) [0|1] ""  Control
 SG_ NLG_E_Crash : 23|1@0+ (1,0) [0|1] ""  Control
 SG_ NLG_E_CanValue : 17|1@0+ (1,0) [0|1] ""  Control
 SG_ NLG_E_CanMsgLost : 16|1@0+ (1,0) [0|1] ""  Control
 SG_ NLG_W_Watchdog : 39|1@0+ (1,0) [0|1] ""  Control
 SG_ NLG_W_CanTx : 51|1@0+ (1,0) [0|1] ""  Control
 SG_ NLG_W_CanRx : 50|1@0+ (1,0) [0|1] ""  Control
 SG_ NLG_W_CanOff : 49|1@0+ (1,0) [0|1] ""  Control
 SG_ NLG_E_OsTrap : 7|1@0+ (1,0) [0|1] ""  Control

BO_ 1809 NLG_DEM_LIM: 8 Control
 SG_ NLG_LedDem : 39|4@0+ (1,0) [0|1] ""  NLG6
 SG_ NLG_C_EnPhaseShift : 52|1@0+ (1,0) [0|1] ""  NLG6
 SG_ NLG_AcPhaseShift : 51|12@0+ (0.1,0) [0|360] "°"  NLG6
 SG_ NLG_C_UnlockConRq : 6|1@0+ (1,0) [0|1] ""  NLG6
 SG_ NLG_C_VentiRq : 5|1@0+ (1,0) [0|1] ""  NLG6
 SG_ NLG_StateDem : 23|3@0+ (1,0) [0|1] ""  NLG6
 SG_ NLG_C_ClrError : 7|1@0+ (1,0) [0|1] ""  NLG6
 SG_ NLG_AcCurrLimMax : 34|11@0+ (0.1,-102.4) [-32|32] "A"  NLG6
 SG_ NLG_DcHvCurrLimMax : 18|11@0+ (0.1,-102.4) [-62.5|62.5] "A"  NLG6
 SG_ NLG_DcHvVoltLimMax : 4|13@0+ (0.1,0) [350|450] "V"  NLG6
